# nrf5340_application register map
Vendor: Nordic Semiconductor; Series: nrf53; File version: 1
CPU: CM33 r0p4, little endian, MPU, FPU, 3 interrupt priority bits, 69 interrupts
Registers are 32-bit, read-write, reset 0x0 unless marked. A register's access mark holds for its fields unless they carry their own. Offsets are from the block's base; [hi:lo] are bit positions.

## NVMC_NS — Non-volatile memory controller 0
Base 0x40039000; alternate view of KMU_NS
Same registers: NVMC_S 0x50039000 (alternate view of KMU_S)
0x400 READY ro reset 0x1 — Ready flag
  [0] READY — NVMC is ready or busy
    0=Busy (NVMC is busy (ongoing write or erase operation)); 1=Ready (NVMC is ready)
0x408 READYNEXT ro reset 0x1 — Ready flag
  [0] READYNEXT — NVMC can accept a new write operation
    0=Busy (NVMC cannot accept any write operation); 1=Ready (NVMC is ready)
0x504 CONFIG — Configuration register
  [2:0] WEN — Program memory access mode. It is strongly recommended to only activate erase and write modes when they are actively used.
    0=Ren (Read only access); 1=Wen (Write enabled); 2=Een (Erase enabled); 4=PEen (Partial erase enabled)
0x50C ERASEALL wo — Register for erasing all non-volatile user memory
  [0] ERASEALL — Erase all non-volatile memory including UICR registers. Before the non-volatile memory can be erased, erasing must be enabled by setting CONFIG.WEN=Een.
    0=NoOperation; 1=Erase (Start chip erase)
0x51C ERASEPAGEPARTIALCFG reset 0xA — Register for partial erase configuration
  [6:0] DURATION — Duration of the partial erase in milliseconds
0x584 CONFIGNS — Non-secure configuration register
  [1:0] WEN — Program memory access mode. It is strongly recommended to only activate erase and write modes when they are actively used.
    0=Ren (Read only access); 1=Wen (Write enabled); 2=Een (Erase enabled)
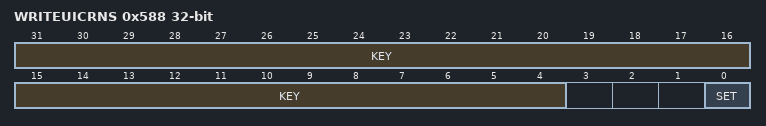
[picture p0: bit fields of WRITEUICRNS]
0x588 WRITEUICRNS wo — Non-secure APPROTECT enable register
  [31:4] KEY — Key to write in order to validate the write operation
    0xAFBE5A7=Keyvalid (Key value)
  [0] SET — Allow non-secure code to set APPROTECT
    1=Set (Set value)

## CRYPTOCELL_S — CRYPTOCELL register interface
Base 0x50844000
0x500 ENABLE — Enable CRYPTOCELL subsystem.
  [0] ENABLE — Enable or disable the CRYPTOCELL subsystem.
    0=Disabled (CRYPTOCELL subsystem disabled.); 1=Enabled (CRYPTOCELL subsystem enabled.)

## CC_AHB_S — CRYPTOCELL AHB interface
Base 0x50845000; alternate view of CC_AES_S
0xB00 AHBM_SINGLES — This register forces the AHB transactions from CRYPTOCELL master to be always singles.
  [0] AHB_SINGLES — Force AHB singles
0xB04 AHBM_HPROT — This register holds the AHB HPROT value
  [3:0] AHB_HPROT — The AHB HPROT value
0xB08 AHBM_HMASTLOCK — This register holds AHB HMASTLOCK value
  [0] AHB_HMASTLOCK — The AHB HMASTLOCK value.
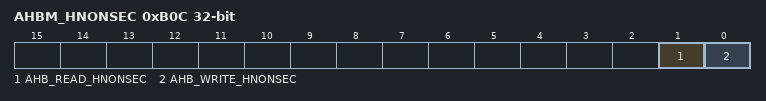
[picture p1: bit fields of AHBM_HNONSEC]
0xB0C AHBM_HNONSEC — This register holds AHB HNONSEC value
  [1] AHB_READ_HNONSEC — The AHB HNONSEC value for read transaction.
  [0] AHB_WRITE_HNONSEC — The AHB HNONSEC value for write transaction.

## CC_AO_S — CryptoCell AO
Base 0x50845000; alternate view of CC_AES_S
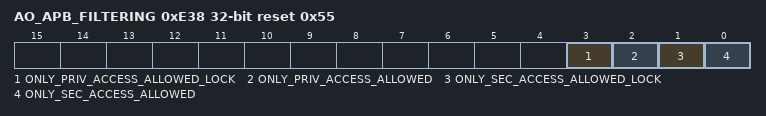
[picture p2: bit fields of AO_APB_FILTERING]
0xE38 AO_APB_FILTERING reset 0x55 — This register holds the AO_APB_FILTERING configuration.
  [3] ONLY_PRIV_ACCESS_ALLOWED_LOCK — When this FW controlled field is set, the APBC_ONLY_PRIV_ACCESS_ALLOWED field cannot be modified until the next PoR
  [2] ONLY_PRIV_ACCESS_ALLOWED — When this FW controlled field is set, the APB slave accepts only privileged accesses
  [1] ONLY_SEC_ACCESS_ALLOWED_LOCK — When this FW controlled field is set, the ONLY_SEC_ACCESS_ALLOWED field cannot be modified until the next PoR
  [0] ONLY_SEC_ACCESS_ALLOWED — When this FW controlled field is set, the APB slave accepts only secure accesses
0xE40 CC_SW_RESET wo — Reset the CRYPTOCELL subsystem.
  [0] RESET — Writing any value to this address resets the CRYPTOCELL subsystem. The reset takes 4 CPU clock cycles to complete.
    1=Enable (Reset CRYPTOCELL subsystem.)

## CC_CTL_S — CRYPTOCELL CTL interface
Base 0x50845000; alternate view of CC_AES_S
0x900 CRYPTO_CTL wo — Defines the cryptographic flow.
  [4:0] MODE — Configure the cryptographic engine mode.
    0=Bypass cryptographic engine; 1=AESActive (Use AES engine); 2=AESToHashActive (Pipe AES engine output to HASH engine input); 3=AESAndHashActive (Process input using both AES and HASH engine in parallell); 7=HashActive (Use HASH engine); 9=AESMACAndBypassActive (Calculate AES MAC and bypass); 10=AESToHashAndDOUTActive (Pipe AES engine output to HASH engine input. The resulting digest output is piped to DOUT buffer.); 16=ChaChaActive (Use CHACHA engine)
0x910 CRYPTO_BUSY ro — Status register for cryptographic cores engine activity.
  [0] STATUS — Cryptographic core engines status.
    0=Idle (Cryptographic core engines are idle); 1=Busy (Cryptographic core engines are busy)
0x91C HASH_BUSY ro — Status register for HASH engine activity.
  [0] STATUS — Hash engine status.
    0=Idle (HASH engine is idle); 1=Busy (HASH engine is busy)
0x930 CONTEXT_ID — A general-purpose read/write register.
  [7:0] CONTEXT_ID
